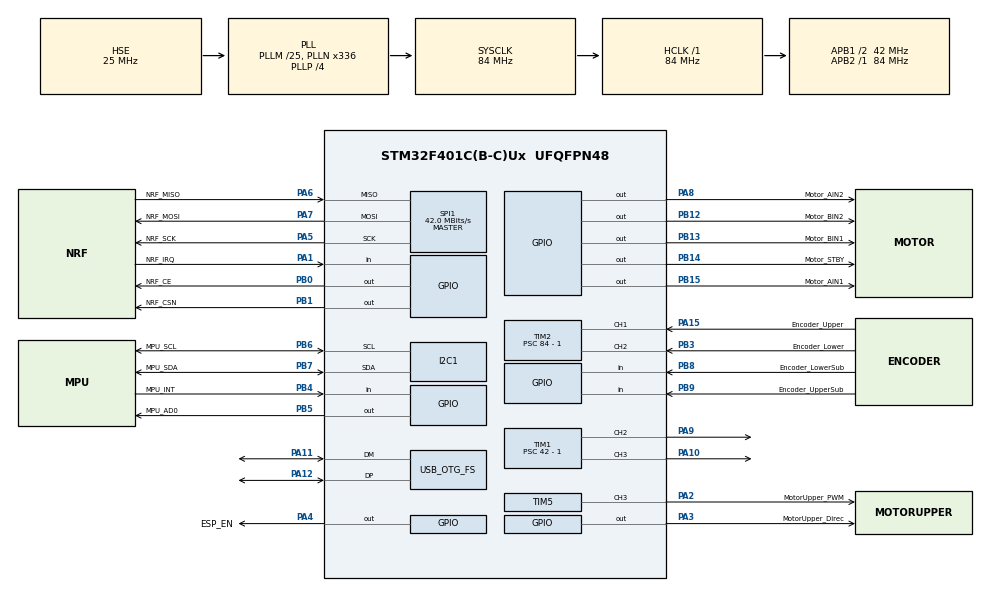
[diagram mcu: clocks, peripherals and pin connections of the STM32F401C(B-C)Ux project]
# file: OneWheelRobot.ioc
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FREERTOS.Tasks01=MainMotionTask,2,1024,StartMainTask,Default,NULL,Dynamic,NULL,NULL
FREERTOS.configENABLE_FPU=1
Mcu.Family=STM32F4
Mcu.Name=STM32F401C(B-C)Ux
Mcu.Package=UFQFPN48
Mcu.UserConstants=TIM2_EncodeManually,1;TIM10_period,1;Uart1_Debug,1;Uart2_ESP32,1;I2C1_MPU,1;TIM1_PWMGenerate,1;SPI1_NRF,1;TIM9_MicroSecond,1
NVIC.OTG_FS_IRQn=true\:6\:0\:true\:false\:true\:true\:false\:true
NVIC.PriorityGroup=NVIC_PRIORITYGROUP_4
NVIC.TIM1_BRK_TIM9_IRQn=true\:5\:0\:true\:false\:true\:true\:true\:true
NVIC.TIM1_TRG_COM_TIM11_IRQn=true\:6\:0\:true\:false\:true\:false\:false\:true
NVIC.TIM1_UP_TIM10_IRQn=true\:6\:0\:true\:false\:true\:true\:true\:true
NVIC.TIM2_IRQn=true\:6\:0\:true\:false\:true\:true\:true\:true
NVIC.TimeBase=TIM1_TRG_COM_TIM11_IRQn
NVIC.TimeBaseIP=TIM11
PA1.GPIO_Label=NRF_IRQ
PA1.Signal=GPIO_Input
PA10.Signal=S_TIM1_CH3
PA11.Mode=Device_Only
PA11.Signal=USB_OTG_FS_DM
PA12.Mode=Device_Only
PA12.Signal=USB_OTG_FS_DP
PA13.Mode=Serial_Wire
PA13.Signal=SYS_JTMS-SWDIO
PA14.Mode=Serial_Wire
PA14.Signal=SYS_JTCK-SWCLK
PA15.GPIO_Label=Encoder_Upper
PA15.Signal=S_TIM2_CH1_ETR
PA2.GPIO_Label=MotorUpper_PWM
PA2.Signal=S_TIM5_CH3
PA3.GPIO_Label=MotorUpper_Direc
PA3.Signal=GPIO_Output
PA4.GPIO_Label=ESP_EN
PA4.GPIO_ModeDefaultOutputPP=GPIO_MODE_OUTPUT_OD
PA4.Signal=GPIO_Output
PA5.GPIO_Label=NRF_SCK
PA5.Mode=Full_Duplex_Master
PA5.Signal=SPI1_SCK
PA6.GPIO_Label=NRF_MISO
PA6.Mode=Full_Duplex_Master
PA6.Signal=SPI1_MISO
PA7.GPIO_Label=NRF_MOSI
PA7.Mode=Full_Duplex_Master
PA7.Signal=SPI1_MOSI
PA8.GPIO_Label=Motor_AIN2
PA8.Signal=GPIO_Output
PA9.Signal=S_TIM1_CH2
PB0.GPIO_Label=NRF_CE
PB0.Signal=GPIO_Output
PB1.GPIO_Label=NRF_CSN
PB1.Signal=GPIO_Output
PB12.GPIO_Label=Motor_BIN2
PB12.Signal=GPIO_Output
PB13.GPIO_Label=Motor_BIN1
PB13.Signal=GPIO_Output
PB14.GPIO_Label=Motor_STBY
PB14.Signal=GPIO_Output
PB15.GPIO_Label=Motor_AIN1
PB15.Signal=GPIO_Output
PB3.GPIO_Label=Encoder_Lower
PB3.Signal=S_TIM2_CH2
PB4.GPIO_Label=MPU_INT
PB4.Signal=GPIO_Input
PB5.GPIO_Label=MPU_AD0
PB5.Signal=GPIO_Output
PB6.GPIO_Label=MPU_SCL
PB6.Mode=I2C
PB6.Signal=I2C1_SCL
PB7.GPIO_Label=MPU_SDA
PB7.Mode=I2C
PB7.Signal=I2C1_SDA
PB8.GPIO_Label=Encoder_LowerSub
PB8.Signal=GPIO_Input
PB9.GPIO_Label=Encoder_UpperSub
PB9.Signal=GPIO_Input
PH0\ -\ OSC_IN.Mode=HSE-External-Oscillator
PH0\ -\ OSC_IN.Signal=RCC_OSC_IN
PH1\ -\ OSC_OUT.Mode=HSE-External-Oscillator
PH1\ -\ OSC_OUT.Signal=RCC_OSC_OUT
ProjectManager.HeapSize=0x800
ProjectManager.StackSize=0x400
ProjectManager.TargetToolchain=MDK-ARM V5
RCC.48MHZClocksFreq_Value=48000000
RCC.AHBFreq_Value=84000000
RCC.APB1CLKDivider=RCC_HCLK_DIV2
RCC.APB1Freq_Value=42000000
RCC.APB1TimFreq_Value=84000000
RCC.APB2Freq_Value=84000000
RCC.APB2TimFreq_Value=84000000
RCC.CortexFreq_Value=84000000
RCC.EnbaleCSS=true
RCC.HCLKFreq_Value=84000000
RCC.HSE_VALUE=25000000
RCC.HSI_VALUE=16000000
RCC.LSE_VALUE=32768
RCC.PLLM=25
RCC.PLLN=336
RCC.PLLP=RCC_PLLP_DIV4
RCC.PLLQ=7
RCC.SYSCLKFreq_VALUE=84000000
RCC.SYSCLKSource=RCC_SYSCLKSOURCE_PLLCLK
RCC.VCOOutputFreq_Value=336000000
SH.S_TIM1_CH2.0=TIM1_CH2,PWM Generation2 CH2
SH.S_TIM1_CH3.0=TIM1_CH3,PWM Generation3 CH3
SH.S_TIM2_CH1_ETR.0=TIM2_CH1,Input_Capture1_from_TI1
SH.S_TIM2_CH2.0=TIM2_CH2,Input_Capture2_from_TI2
SH.S_TIM5_CH3.0=TIM5_CH3,PWM Generation3 CH3
SPI1.BaudRatePrescaler=SPI_BAUDRATEPRESCALER_2
SPI1.CalculateBaudRate=42.0 MBits/s
SPI1.Direction=SPI_DIRECTION_2LINES
SPI1.Mode=SPI_MODE_MASTER
SPI1.VirtualType=VM_MASTER
TIM1.Channel-PWM\ Generation2\ CH2=TIM_CHANNEL_2
TIM1.Channel-PWM\ Generation3\ CH3=TIM_CHANNEL_3
TIM1.OCPolarity_2=TIM_OCPOLARITY_LOW
TIM1.Period=1000 - 1
TIM1.Prescaler=42 - 1
TIM10.Period=1000 - 1
TIM10.Prescaler=84 - 1
TIM2.Channel-Input_Capture1_from_TI1=TIM_CHANNEL_1
TIM2.Channel-Input_Capture2_from_TI2=TIM_CHANNEL_2
TIM2.Period=65535
TIM2.Prescaler=84 - 1
TIM5.Channel-PWM\ Generation3\ CH3=TIM_CHANNEL_3
TIM5.Period=1000 - 1
TIM5.Prescaler=42 - 1
TIM9.Period=65535
TIM9.Prescaler=84 - 1
USB_DEVICE.CLASS_NAME_FS=CDC
USB_DEVICE.VirtualMode=Cdc
USB_DEVICE.VirtualModeFS=Cdc_FS
USB_OTG_FS.VirtualMode=Device_Only
VP_FREERTOS_VS_CMSIS_V1.Mode=CMSIS_V1
VP_SYS_VS_tim11.Mode=TIM11
VP_TIM10_VS_ClockSourceINT.Mode=Enable_Timer
VP_TIM1_VS_ClockSourceINT.Mode=Internal
VP_TIM2_VS_ClockSourceINT.Mode=Internal
VP_TIM9_VS_ClockSourceINT.Mode=Internal
VP_USB_DEVICE_VS_USB_DEVICE_CDC_FS.Mode=CDC_FS
board=custom

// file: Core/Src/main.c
/* USER CODE BEGIN Header */
/**
  ******************************************************************************
  * @file           : main.c
  * @brief          : Main program body
  ******************************************************************************
  * @attention
  *
  * <h2><center>&copy; Copyright (c) 2021 STMicroelectronics.
  * All rights reserved.</center></h2>
  *
  * This software component is licensed by ST under Ultimate Liberty license
  * SLA0044, the "License"; You may not use this file except in compliance with
  * the License. You may obtain a copy of the License at:
  *                             www.st.com/SLA0044
  *
  ******************************************************************************
  */
/* USER CODE END Header */
#include "main.h"
#include "cmsis_os.h"
#include "i2c.h"
#include "spi.h"
#include "tim.h"
#include "usb_device.h"
#include "gpio.h"

/* USER CODE BEGIN Includes */
#include "main_.h"

/* USER CODE END Includes */

void SystemClock_Config(void);
void MX_FREERTOS_Init(void);

int main(void)
{

  /* MCU Configuration--------------------------------------------------------*/

  /* Reset of all peripherals, Initializes the Flash interface and the Systick. */
  HAL_Init();

  /* Configure the system clock */
  SystemClock_Config();

  /* Initialize all configured peripherals */
  MX_GPIO_Init();
  MX_I2C1_Init();
  MX_TIM2_Init();
  MX_TIM10_Init();
  MX_SPI1_Init();
  MX_TIM1_Init();
  MX_TIM9_Init();
  MX_TIM5_Init();

  /* Call init function for freertos objects (in freertos.c) */
  MX_FREERTOS_Init();
  /* Start scheduler */
  osKernelStart();

  /* We should never get here as control is now taken by the scheduler */
  /* Infinite loop */
  while (1)
  {

  }
}

void SystemClock_Config(void)
{
  RCC_OscInitTypeDef RCC_OscInitStruct = {0};
  RCC_ClkInitTypeDef RCC_ClkInitStruct = {0};

  /** Configure the main internal regulator output voltage
  */
  __HAL_RCC_PWR_CLK_ENABLE();
  __HAL_PWR_VOLTAGESCALING_CONFIG(PWR_REGULATOR_VOLTAGE_SCALE2);
  /** Initializes the RCC Oscillators according to the specified parameters
  * in the RCC_OscInitTypeDef structure.
  */
  RCC_OscInitStruct.OscillatorType = RCC_OSCILLATORTYPE_HSE;
  RCC_OscInitStruct.HSEState = RCC_HSE_ON;
  RCC_OscInitStruct.PLL.PLLState = RCC_PLL_ON;
  RCC_OscInitStruct.PLL.PLLSource = RCC_PLLSOURCE_HSE;
  RCC_OscInitStruct.PLL.PLLM = 25;
  RCC_OscInitStruct.PLL.PLLN = 336;
  RCC_OscInitStruct.PLL.PLLP = RCC_PLLP_DIV4;
  RCC_OscInitStruct.PLL.PLLQ = 7;
  if (HAL_RCC_OscConfig(&RCC_OscInitStruct) != HAL_OK)
  {
    Error_Handler();
  }
  /** Initializes the CPU, AHB and APB buses clocks
  */
  RCC_ClkInitStruct.ClockType = RCC_CLOCKTYPE_HCLK|RCC_CLOCKTYPE_SYSCLK
                              |RCC_CLOCKTYPE_PCLK1|RCC_CLOCKTYPE_PCLK2;
  RCC_ClkInitStruct.SYSCLKSource = RCC_SYSCLKSOURCE_PLLCLK;
  RCC_ClkInitStruct.AHBCLKDivider = RCC_SYSCLK_DIV1;
  RCC_ClkInitStruct.APB1CLKDivider = RCC_HCLK_DIV2;
  RCC_ClkInitStruct.APB2CLKDivider = RCC_HCLK_DIV1;

  if (HAL_RCC_ClockConfig(&RCC_ClkInitStruct, FLASH_LATENCY_2) != HAL_OK)
  {
    Error_Handler();
  }
  /** Enables the Clock Security System
  */
  HAL_RCC_EnableCSS();
}

void HAL_TIM_PeriodElapsedCallback(TIM_HandleTypeDef *htim)
{
  if (htim->Instance == TIM11) {
    HAL_IncTick();
  }
  /* USER CODE BEGIN Callback 1 */
  Main_TIM_ElapsedHandler(htim);

  /* USER CODE END Callback 1 */
}

void Error_Handler(void)
{
  __disable_irq();
  while (1)
  {
  }
}

/************************ (C) COPYRIGHT STMicroelectronics *****END OF FILE****/

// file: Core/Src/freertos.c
/* USER CODE BEGIN Header */
/**
  ******************************************************************************
  * File Name          : freertos.c
  * Description        : Code for freertos applications
  ******************************************************************************
  * @attention
  *
  * <h2><center>&copy; Copyright (c) 2021 STMicroelectronics.
  * All rights reserved.</center></h2>
  *
  * This software component is licensed by ST under Ultimate Liberty license
  * SLA0044, the "License"; You may not use this file except in compliance with
  * the License. You may obtain a copy of the License at:
  *                             www.st.com/SLA0044
  *
  ******************************************************************************
  */
/* USER CODE END Header */

#include "FreeRTOS.h"
#include "task.h"
#include "main.h"
#include "cmsis_os.h"

/* USER CODE BEGIN Includes */
#include "main_.h"
#include "debug.h"

/* USER CODE END Includes */

osThreadId MainMotionTaskHandle;

void StartMainTask(void const * argument);

extern void MX_USB_DEVICE_Init(void);
void MX_FREERTOS_Init(void); /* (MISRA C 2004 rule 8.1) */

/* GetIdleTaskMemory prototype (linked to static allocation support) */
void vApplicationGetIdleTaskMemory( StaticTask_t **ppxIdleTaskTCBBuffer, StackType_t **ppxIdleTaskStackBuffer, uint32_t *pulIdleTaskStackSize );

/* USER CODE BEGIN GET_IDLE_TASK_MEMORY */
static StaticTask_t xIdleTaskTCBBuffer;
static StackType_t xIdleStack[configMINIMAL_STACK_SIZE];

void vApplicationGetIdleTaskMemory( StaticTask_t **ppxIdleTaskTCBBuffer, StackType_t **ppxIdleTaskStackBuffer, uint32_t *pulIdleTaskStackSize )
{
  *ppxIdleTaskTCBBuffer = &xIdleTaskTCBBuffer;
  *ppxIdleTaskStackBuffer = &xIdleStack[0];
  *pulIdleTaskStackSize = configMINIMAL_STACK_SIZE;
  /* place for user code */
}
/* USER CODE END GET_IDLE_TASK_MEMORY */

void MX_FREERTOS_Init(void) {

  /* Create the thread(s) */
  /* definition and creation of MainMotionTask */
  osThreadDef(MainMotionTask, StartMainTask, osPriorityHigh, 0, 1024);
  MainMotionTaskHandle = osThreadCreate(osThread(MainMotionTask), NULL);

}

void StartMainTask(void const * argument)
{
  /* init code for USB_DEVICE */
  MX_USB_DEVICE_Init();
  /* USER CODE BEGIN StartMainTask */
  Main_Process();
  /* Infinite loop */
  for(;;)
  {
    osDelay(1);
  }
  /* USER CODE END StartMainTask */
}

/************************ (C) COPYRIGHT STMicroelectronics *****END OF FILE****/
